# STM32H7B3xxQ register map
File version: 1.0
Registers are 32-bit, read-write, reset 0x0 unless marked. A register's access mark holds for its fields unless they carry their own. Offsets are from the block's base; [hi:lo] are bit positions; {n}, {i} and the like mark numbered series; 'fields as' and 'values as' point back to an identical list.

## COMP1
Base 0x5800380C
Same registers: COMP2 0x58003810
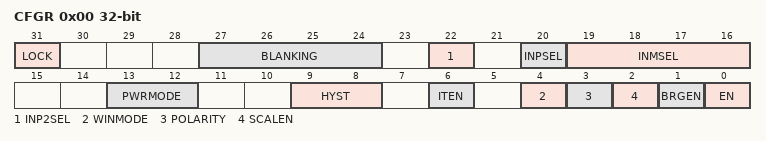
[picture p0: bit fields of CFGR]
0x00 CFGR — Comparator configuration register
  [31] LOCK — COMPx Lock Bit
  [27:24] BLANKING — COMPx blanking source selection bits
    0=NONE (Comparator output without blanking); 1=TIM1_OC5 (Comparator output blanking source TIM1 OC5 (common to all COMP instances: COMP1, COMP2)); 2=TIM2_OC3 (Comparator output blanking source TIM2 OC3 (common to all COMP instances: COMP1, COMP2)); 3=TIM3_OC3 (Comparator output blanking source TIM3 OC3 (common to all COMP instances: COMP1, COMP2)); 4=TIM3_OC4 (Comparator output blanking source TIM3 OC4 (common to all COMP instances: COMP1, COMP2)); 5=TIM8_OC5 (Comparator output blanking source TIM8 OC5 (common to all COMP instances: COMP1, COMP2)); 6=TIM15_OC1 (Comparator output blanking source TIM15 OC1 (common to all COMP instances: COMP1, COMP2))
  [22] INP2SEL — COMPx input plus 2 selection bit
  [20] INPSEL — COMPx input plus selection bit
  [19:16] INMSEL — COMPx input minus selection bit
  [13:12] PWRMODE — COMPx Power Mode of the comparator
    0=HIGHSPEED (COMP power mode to high speed); 1=MEDIUMSPEED (COMP power mode to medium speed); 3=ULTRALOWPOWER (COMP power mode to ultra-low power)
  [9:8] HYST — COMPx hysteresis selection bits
    0=NONE (No hysteresis); 1=LOW (Hysteresis level low); 2=MEDIUM (Hysteresis level medium); 3=HIGH (Hysteresis level high)
  [6] ITEN — COMPx interrupt enable
  [4] WINMODE — COMPx Windows mode selection bit
    0=DISABLE (Window mode disable: Comparators 1 and 2 are independent); 1=COMP1_INPUT_PLUS_COMMON (Window mode enable: Comparators instances pair COMP1 and COMP2 have their input plus connected together. The common input is COMP1 input plus (COMP2 input plus is no more accessible).)
  [3] POLARITY — COMPx polarity selection bit
    0=NONINVERTED (COMP output polarity is not inverted: comparator output is high when the plus (non-inverting) input is at a higher voltage than the minus (inverting) input); 1=INVERTED (COMP output polarity is inverted: comparator output is low when the plus (non-inverting) input is at a lower voltage than the minus (inverting) input)
  [2] SCALEN — COMPx Voltage scaler enable bit
  [1] BRGEN — COMPx Scaler bridge enable
  [0] EN — COMPx enable bit

## VREFBUF
Base 0x58003C00
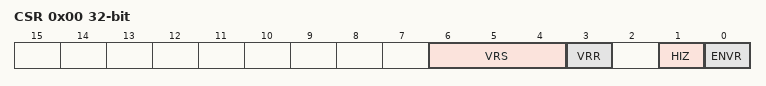
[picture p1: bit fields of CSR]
0x00 CSR — VREFBUF control and status register
  [6:4] VRS — Voltage reference scale
  [3] VRR — Voltage reference buffer ready
  [1] HIZ — High impedance mode
  [0] ENVR — Voltage reference buffer enable
0x04 CCR — VREFBUF calibration and control register
  [5:0] TRIM — TRIM[5:0] bits (Trimming code)

## RTC — Real-Time Clock
Base 0x58004000
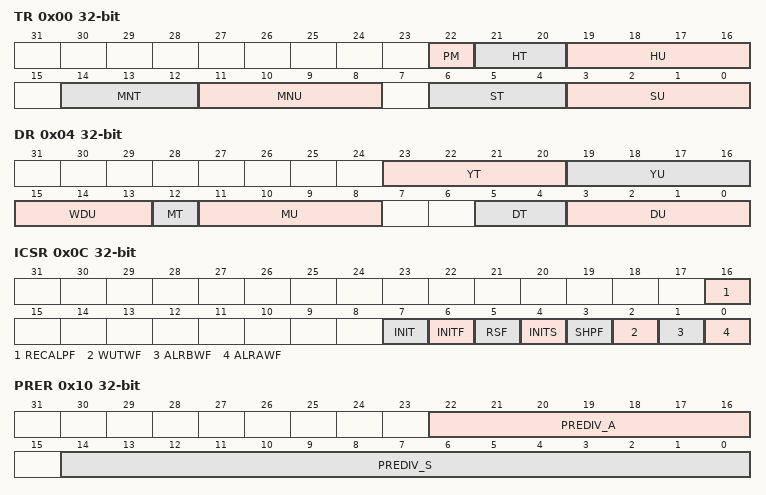
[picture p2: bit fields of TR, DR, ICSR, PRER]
0x00 TR — RTC time register
  [22] PM
    0=AM_OR_24 (AM or 24-hour format); 1=PM
  [21:20] HT
  [19:16] HU
  [14:12] MNT
  [11:8] MNU
  [6:4] ST
  [3:0] SU
0x04 DR — RTC date register
  [23:20] YT, [19:16] YU, [15:13] WDU, [12] MT, [11:8] MU, [5:4] DT, [3:0] DU
0x08 SSR — RTC sub second register
  [15:0] SS
0x0C ICSR — RTC initialization control and status register
  [16] RECALPF, [7] INIT, [6] INITF, [5] RSF, [4] INITS, [3] SHPF, [2] WUTWF, [1] ALRBWF, [0] ALRAWF
0x10 PRER — RTC prescaler register
  [22:16] PREDIV_A, [14:0] PREDIV_S
0x14 WUTR — RTC wakeup timer register
  [15:0] WUT
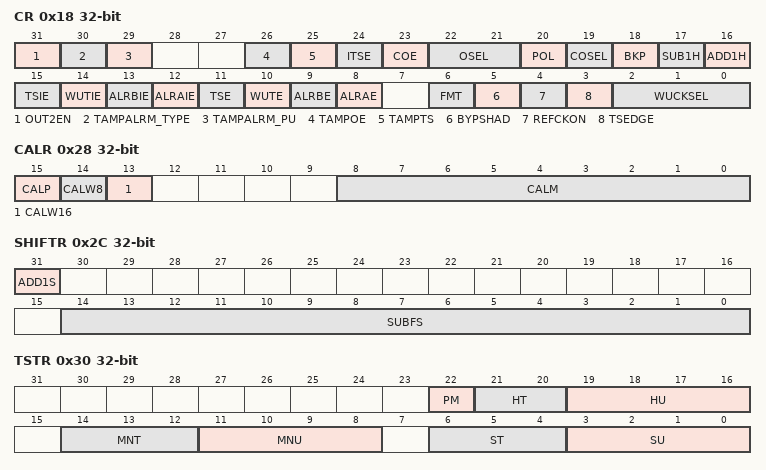
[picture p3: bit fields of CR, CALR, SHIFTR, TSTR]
0x18 CR — RTC control register
  [31] OUT2EN — RTC_OUT2 output enable
  [30] TAMPALRM_TYPE — TAMPALARM output type
    1=OPENDRAIN (RTC_ALARM is open-drain output); 0=PUSHPULL (RTC_ALARM is push-pull output)
  [29] TAMPALRM_PU — TAMPALARM output pull-up config
  [26] TAMPOE — Tamper detection output enable on TAMPALARM
  [25] TAMPTS — Activate timestamp on tamper detection event
  [24] ITSE
  [23] COE
  [22:21] OSEL
    0=DISABLE (Output disabled); 1=ALMA (Alarm A output enabled); 2=ALMB (Alarm B output enabled); 3=WAKEUP (Wakeup output enabled)
  [20] POL
    0=HIGH (Pin is high when ALRAF/ALRBF/WUTF is asserted (depending on OSEL)); 1=LOW (Pin is low when ALRAF/ALRBF/WUTF is asserted (depending on OSEL))
  [19] COSEL
  [18] BKP
  [17] SUB1H
  [16] ADD1H
  [15] TSIE
  [14] WUTIE
  [13] ALRBIE
  [12] ALRAIE
  [11] TSE
  [10] WUTE
  [9] ALRBE
  [8] ALRAE
  [6] FMT
    0=HOURFORMAT_24HOUR (24 hour/day format); 1=AMPM (AM/PM hour format)
  [5] BYPSHAD
  [4] REFCKON
  [3] TSEDGE
    0=RISING (RTC_TS input rising edge generates a time-stamp event); 1=FALLING (RTC_TS input falling edge generates a time-stamp even)
  [2:0] WUCKSEL
    0=DIV_16 (RTC/16 clock is selected); 1=DIV_8 (RTC/8 clock is selected); 2=DIV_4 (RTC/4 clock is selected); 3=DIV_2 (RTC/2 clock is selected); 4=CKSPRE (ck_spre (usually 1 Hz) clock is selected); 6=CKSPRE_WUT (ck_spre (usually 1 Hz) clock is selected and 2exp16 is added to the WUT counter value)
0x24 WPR — RTC write protection register
  [7:0] KEY
0x28 CALR — RTC calibration register
  [15] CALP
    0=NONE (No RTCCLK pulses are added); 1=SET (One RTCCLK pulse is effectively inserted every 2exp11 pulses (frequency increased by 488.5 ppm))
  [14] CALW8
  [13] CALW16
  [8:0] CALM
0x2C SHIFTR — RTC shift control register
  [31] ADD1S, [14:0] SUBFS
0x30 TSTR — RTC time stamp time register
  [22] PM
    0=AM (AM or 24-hour format); 1=PM
  [21:20] HT
  [19:16] HU
  [14:12] MNT
  [11:8] MNU
  [6:4] ST
  [3:0] SU
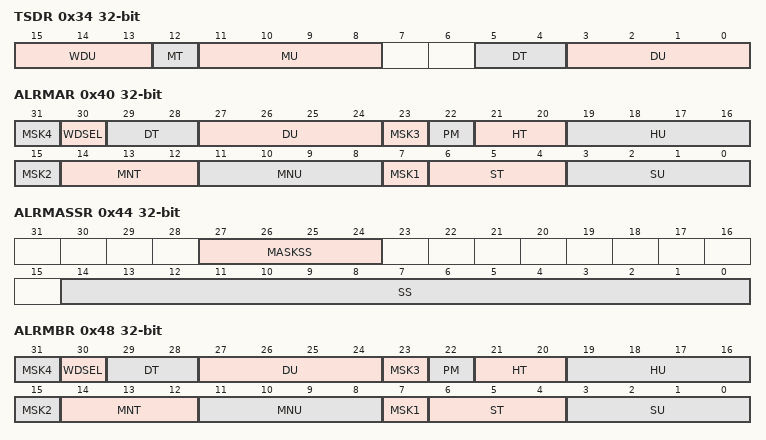
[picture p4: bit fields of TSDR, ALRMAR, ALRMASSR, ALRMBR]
0x34 TSDR — RTC time stamp date register
  [15:13] WDU, [12] MT, [11:8] MU, [5:4] DT, [3:0] DU
0x38 TSSSR — RTC time-stamp sub second register
  [15:0] SS
0x40 ALRMAR — RTC alarm A register
  [8n-1] MSK{n} (n=1..4)
  [30] WDSEL
  [29:28] DT
  [27:24] DU
  [22] PM
    0=AM (AM or 24-hour format); 1=PM
  [21:20] HT
  [19:16] HU
  [14:12] MNT
  [11:8] MNU
  [6:4] ST
  [3:0] SU
0x44 ALRMASSR — RTC alarm A sub second register
  [27:24] MASKSS, [14:0] SS
0x48 ALRMBR — RTC alarm B register
  fields as ALRMAR
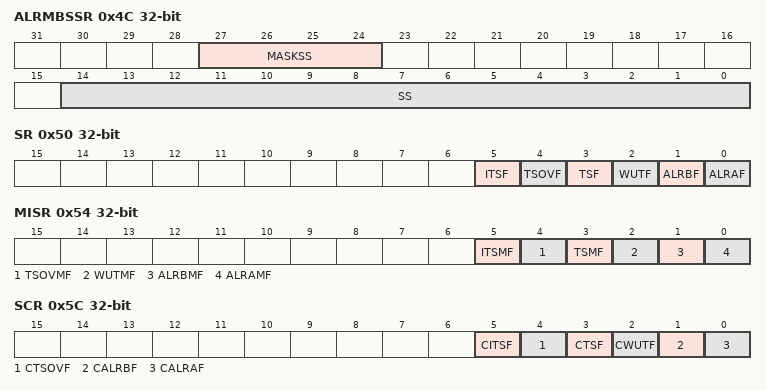
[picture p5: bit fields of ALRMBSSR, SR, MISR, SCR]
0x4C ALRMBSSR — RTC alarm B sub second register
  [27:24] MASKSS, [14:0] SS
0x50 SR — RTC Status register
  [5] ITSF, [4] TSOVF, [3] TSF, [2] WUTF, [1] ALRBF, [0] ALRAF
0x54 MISR — RTC masked interrupt status register
  [5] ITSMF, [4] TSOVMF, [3] TSMF, [2] WUTMF, [1] ALRBMF, [0] ALRAMF
0x5C SCR — RTC status Clear register
  [5] CITSF, [4] CTSOVF, [3] CTSF, [2] CWUTF, [1] CALRBF, [0] CALRAF
0x60 CFGR — RTC configuration register
